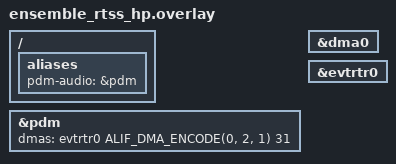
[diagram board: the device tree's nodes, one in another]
/* Copyright (C) 2024 Alif Semiconductor - All Rights Reserved.
 * Use, distribution and modification of this code is permitted under the
 * terms stated in the Alif Semiconductor Software License Agreement
 *
 * You should have received a copy of the Alif Semiconductor Software
 * License Agreement with this file. If not, please write to:
 * contact@alifsemi.com, or visit: https://alifsemi.com/license
 *
 */
#include <zephyr/dt-bindings/dma/alif_dma_event_router.h>
/ {
	aliases {
		pdm-audio = &pdm;
	};
};

&pdm {
	status = "okay";
	dmas = <&evtrtr0 ALIF_DMA_ENCODE(0, 2, 1) 31>;
	dma-names = "rxdma";
};
&dma0 {
	status = "okay";
};
&evtrtr0 {
	status = "okay";
};
